# psc3_p8_ppca register map
Vendor: Infineon Technologies; Series: PSC3_P8; File version: 1.0
CPU: CM33 r0p1, little endian, MPU, FPU, DSP, VTOR, 3 interrupt priority bits, 143 interrupts
Registers are 32-bit, read-write, reset 0x0 unless marked. A register's access mark holds for its fields unless they carry their own. Offsets are from the block's base; [hi:lo] are bit positions; {n}, {i} and the like mark numbered series.

## MXCM33 — MXCM33-0/1
Base 0x68160000
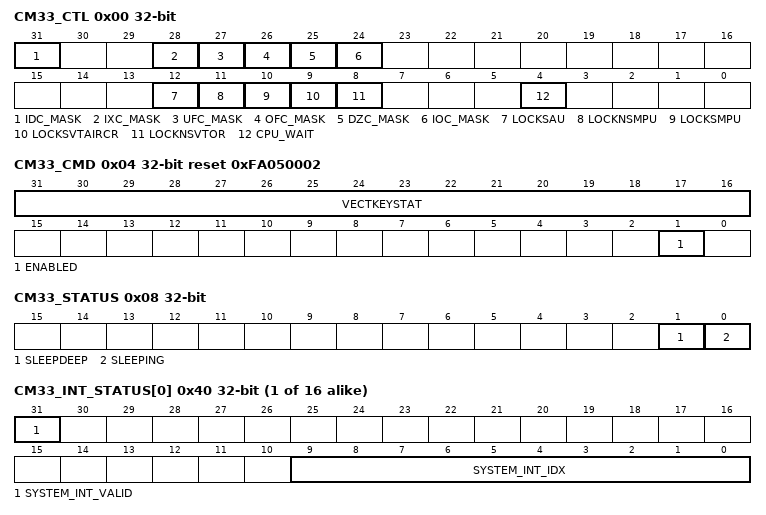
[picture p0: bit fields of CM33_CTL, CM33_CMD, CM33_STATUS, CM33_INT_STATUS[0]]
0x00 CM33_CTL — Control
  [31] IDC_MASK
  [28] IXC_MASK
  [27] UFC_MASK
  [26] OFC_MASK
  [25] DZC_MASK
  [24] IOC_MASK — CPU floating point unit (FPU) exception mask for the CPU's FPCSR.IOC 'invalid operation' exception condition: '0': The CPU's exception condition does NOT activate the CPU's floating point interrupt. '1': the CPU's exception condition activates the CPU's floating point interrupt. Note: the ARM architecture does NOT support FPU exceptions; i.e. there is no precise FPU exception handler. Instead, FPU conditions are captured in the CPU's FPCSR register and the conditions are provided as CPU interface signals. The interface signals are 'masked' with the fields provided by this register (CM33_CTL). The 'masked' signals are reduced/OR-ed into a single CPU floating point interrupt signal. The associated CPU interrupt handler allows for imprecise handling of FPU exception conditions. Note: the CPU's FPCSR exception conditions are 'sticky'. Typically, the CPU FPU interrupt handler will clear the exception condition(s) to '0'. Note: by default, the FPU exception masks are '0'. Therefore, FPU exception conditions will NOT activate the CPU's floating point interrupt.
  [12] LOCKSAU
  [11] LOCKNSMPU
  [10] LOCKSMPU
  [9] LOCKSVTAIRCR
  [8] LOCKNSVTOR
  [4] CPU_WAIT
0x04 CM33_CMD reset 0xFA050002 — Command
  [31:16] VECTKEYSTAT ro — Register key (to prevent accidental writes). - Should be written with a 0x05fa key value for the write to take effect. - Always reads as 0xfa05.
  [1] ENABLED — Processor enable: '0': Disabled. Processor clock is turned off and reset is activated. After SW clears this field to '0', HW automatically sets this field to '1'. This effectively results in a CM33 reset, followed by a CM33 warm boot. '1': Enabled. Note: The intent is that this bit is modified only through an external probe or by the other CM33 while this CM33 is in Sleep or DeepSleep power mode. If this field is cleared to '0' by this CM33 itself, it should be done under controlled conditions (such that undesirable side effects can be prevented). Note: The CM33 CPU has a AIRCR.SYSRESETREQ register field that allows the CM33 to reset the complete device (ENABLED only disables/enables the CM33), resulting in a warm boot. This CPU register field has similar 'built-in protection' as this register to prevent accidental system writes (the upper 16-bits of the register need to be written with a 0x05fa key value; see CPU user manual for more details).
0x08 CM33_STATUS ro — Status
  [1] SLEEPDEEP — Specifies if the CPU is in Sleep or DeepSleep power mode. See SLEEPING field.
  [0] SLEEPING — Specifies if the CPU is in Active, Sleep or DeepSleep power mode: - Active power mode: SLEEPING is '0'. - Sleep power mode: SLEEPING is '1' and SLEEPDEEP is '0'. - DeepSleep power mode: SLEEPING is '1' and SLEEPDEEP is '1'.
{0x40+4i} CM33_INT_STATUS[{i}] (i=0..15) ro (reset mask 0x80000000) — CM33 interrupt status
  [31] SYSTEM_INT_VALID — Valid indication for SYSTEM_INT_IDX. When '0', no system interrupt for CPU interrupt 0 is valid/activated.
  [9:0] SYSTEM_INT_IDX — Lowest CM33 activated system interrupt index for given CPU interrupt. Multiple system interrupts can be mapped on the same CPU interrupt. The selected system interrupt is the system interrupt with the lowest system interrupt index that has an activated interrupt request at the time of the fetch (system_interrupts[SYSTEM_INT_IDX] is '1'). The CPU interrupt handler SW can read SYSTEM_INT_IDX to determine the system interrupt that activated the handler.
{0x80+4i} CM33_NMI_CTL[{i}] (i=0..3) reset 0x3FF — CM33 NMI control
  [9:0] SYSTEM_INT_IDX — System interrupt select for CPU NMI. The reset value ('1023') ensures that the CPU NMI is NOT connected to any system interrupt after DeepSleep reset.
0xC0 CM33_EVENT_CTL — CM33 event control
  [4:0] MASK — One mask bit for each CPU (other than itself). 0: Mask is not set. 1: RX event from the corresponding CPU is masked. Bit 0: Other CM33 CPU event Bit 1: CM55_0 CPU event Bit 2: CM55_1 CPU event Bit 3: CM55_2 CPU event Bit 4: CM55_3 CPU event
0x1000 CM33_S_VECTOR_TABLE_BASE — CM33 secure vector table base
  [31:7] ADDR25 — Address of CM33 secure vector table to be used at reset. Default value: ADDR25: 0x0200000 if PROM is present (points to Secure ROM start address i.e. 0x1000_0000). ADDR25: 0x0680000 if PROM is not present (points to Secure RAMC0 start address i.e. 0x3400_0000).
0x1004 CM33_NS_VECTOR_TABLE_BASE — CM33 non-secure vector table base
  [31:7] ADDR25 — Address of CM33 non-secure vector table to be used at reset. Default value: ADDR25: 0x0000000 if PROM is present (points to Non-Secure ROM start address i.e. 0x0000_0000). ADDR25: 0x0480000 if PROM is not present (points to Non-Secure RAMC0 start address i.e. 0x2400_0000).
0x2000 CM33_PC_CTL — CM33 protection context control
  [3:0] VALID — Valid fields for the protection context handler CM33_PCi_HANDLER registers: Bit 0: Valid field for CM33_PC0_HANDLER. Bit 1: Valid field for CM33_PC1_HANDLER. Bit 2: Valid field for CM33_PC2_HANDLER. Bit 3: Valid field for CM33_PC3_HANDLER.
0x2040 CM33_PC0_HANDLER — CM33 protection context 0 handler
  [31:0] ADDR — Address of the protection context 0 handler. This field is used to detect entry to Cypress 'trusted' code through an exception/interrupt.
{0x20C0+0x40*i} CM33_PC{i}_HANDLER (i=1..3) — CM33 protection context {i} handler
  [31:0] ADDR — Address of the protection context {i} handler.
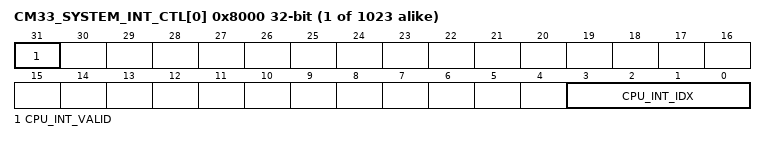
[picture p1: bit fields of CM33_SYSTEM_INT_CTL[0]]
{0x8000+4i} CM33_SYSTEM_INT_CTL[{i}] (i=0..1022) (reset mask 0x80000000) — CM33 system interrupt control
  [31] CPU_INT_VALID — Interrupt enable: '0': Disabled. The system interrupt will NOT be mapped to any CPU interrupt. '1': Enabled. The system interrupt is mapped on CPU interrupt CPU_INT_IDX. Note: the CPUs have dedicated XXX_SYSTEM_INT_CTL registers. In other words, the CPUs can use different CPU interrupts for the same system interrupt. However, typically only one of the CPUs will have the ENABLED field of a specific system interrupt set to '1'.
  [3:0] CPU_INT_IDX — CPU interrupt index (legal range [0, 15]). This field specifies to which CPU interrupt the system interrupt is mapped. E.g., if CPU_INT_IDX is '6', the system interrupt is mapped to CPU interrupt '6'. Note: it is possible to map multiple system interrupts to the same CPU interrupt. It is advised to assign different priorities to the CPU interrupts and to assign system interrupts to CPU interrupts accordingly. Note: CPU_INT_IDX register width is derived from mxcm33 parameter IRQ_IDX_WIDTH. IRQ_IDX_WIDTH = (CM33_INT_NR == 16) ? 4 : 3
